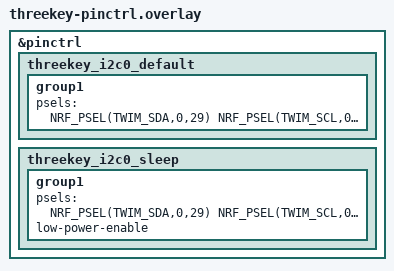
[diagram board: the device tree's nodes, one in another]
/*
 * ThreeKey Keyboard - I2C pin configuration
 *
 * Move I2C from board defaults (SDA=P0.17, SCL=P0.20) to:
 * SDA = P0.29
 * SCL = P0.31
 *
 * Reason: P0.17 / P0.20 are used by KEY1 / KEY2.
 *
 * NOTE: unique labels (threekey_i2c0_*) are required to avoid
 * clashing with the board's i2c0_default / i2c0_sleep labels.
 */


&pinctrl {


    threekey_i2c0_default: threekey_i2c0_default {


        group1 {

            psels = <
                NRF_PSEL(TWIM_SDA,0,29)
                NRF_PSEL(TWIM_SCL,0,31)
            >;

        };

    };



    threekey_i2c0_sleep: threekey_i2c0_sleep {


        group1 {

            psels = <
                NRF_PSEL(TWIM_SDA,0,29)
                NRF_PSEL(TWIM_SCL,0,31)
            >;

            low-power-enable;

        };

    };

};
